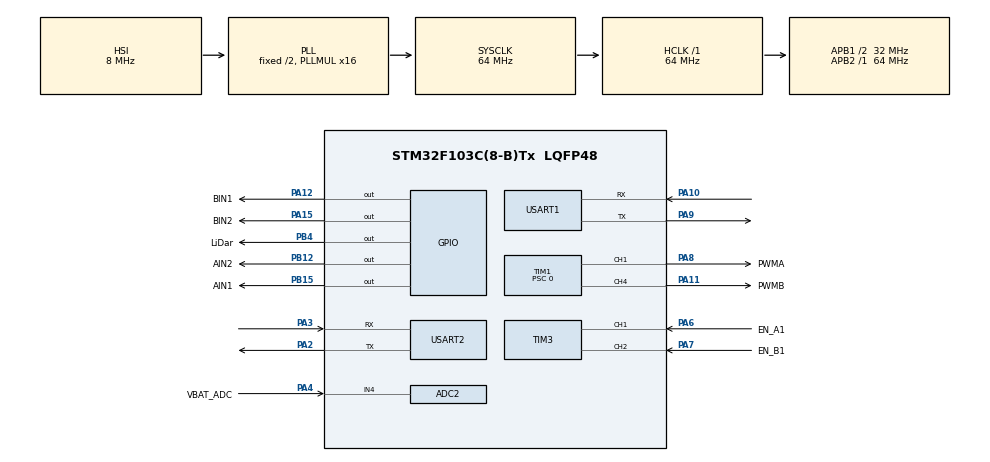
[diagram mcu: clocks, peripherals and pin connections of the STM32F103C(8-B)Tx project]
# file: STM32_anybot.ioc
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ADC2.Channel-0\#ChannelRegularConversion=ADC_CHANNEL_4
ADC2.NbrOfConversionFlag=1
ADC2.Rank-0\#ChannelRegularConversion=1
ADC2.SamplingTime-0\#ChannelRegularConversion=ADC_SAMPLETIME_1CYCLE_5
Mcu.Family=STM32F1
Mcu.Name=STM32F103C(8-B)Tx
Mcu.Package=LQFP48
NVIC.PriorityGroup=NVIC_PRIORITYGROUP_2
NVIC.TIM3_IRQn=true\:1\:0\:true\:false\:true\:true\:true\:true
PA0-WKUP.GPIO_Label=EN_A2
PA0-WKUP.Signal=S_TIM2_CH1_ETR
PA1.GPIO_Label=EN_B2
PA1.Signal=S_TIM2_CH2
PA10.Mode=Asynchronous
PA10.Signal=USART1_RX
PA11.GPIO_Label=PWMB
PA11.Signal=S_TIM1_CH4
PA12.GPIO_Label=BIN1
PA12.GPIO_Speed=GPIO_SPEED_FREQ_HIGH
PA12.Signal=GPIO_Output
PA13.Mode=Serial_Wire
PA13.Signal=SYS_JTMS-SWDIO
PA14.Mode=Serial_Wire
PA14.Signal=SYS_JTCK-SWCLK
PA15.GPIO_Label=BIN2
PA15.GPIO_Speed=GPIO_SPEED_FREQ_HIGH
PA15.Signal=GPIO_Output
PA2.Mode=Asynchronous
PA2.Signal=USART2_TX
PA3.Mode=Asynchronous
PA3.Signal=USART2_RX
PA4.GPIO_Label=VBAT_ADC
PA4.Signal=ADCx_IN4
PA6.GPIO_Label=EN_A1
PA6.Signal=S_TIM3_CH1
PA7.GPIO_Label=EN_B1
PA7.Signal=S_TIM3_CH2
PA8.GPIO_Label=PWMA
PA8.Signal=S_TIM1_CH1
PA9.Mode=Asynchronous
PA9.Signal=USART1_TX
PB12.GPIO_Label=AIN2
PB12.GPIO_Speed=GPIO_SPEED_FREQ_HIGH
PB12.Signal=GPIO_Output
PB15.GPIO_Label=AIN1
PB15.GPIO_Speed=GPIO_SPEED_FREQ_HIGH
PB15.Signal=GPIO_Output
PB4.GPIO_Label=LiDar
PB4.Signal=GPIO_Output
ProjectManager.HeapSize=0x200
ProjectManager.StackSize=0x400
ProjectManager.TargetToolchain=STM32CubeIDE
RCC.ADCPresc=RCC_ADCPCLK2_DIV8
RCC.AHBFreq_Value=64000000
RCC.APB1CLKDivider=RCC_HCLK_DIV2
RCC.APB1Freq_Value=32000000
RCC.APB1TimFreq_Value=64000000
RCC.APB2Freq_Value=64000000
RCC.APB2TimFreq_Value=64000000
RCC.HCLKFreq_Value=64000000
RCC.PLLMUL=RCC_PLL_MUL16
RCC.SYSCLKFreq_VALUE=64000000
RCC.SYSCLKSource=RCC_SYSCLKSOURCE_PLLCLK
RCC.USBFreq_Value=64000000
SH.ADCx_IN4.0=ADC2_IN4,IN4
SH.S_TIM1_CH1.0=TIM1_CH1,PWM Generation1 CH1
SH.S_TIM1_CH4.0=TIM1_CH4,PWM Generation4 CH4
SH.S_TIM2_CH1_ETR.0=TIM2_CH1
SH.S_TIM2_CH2.0=TIM2_CH2
SH.S_TIM3_CH1.0=TIM3_CH1,Encoder_Interface
SH.S_TIM3_CH2.0=TIM3_CH2,Encoder_Interface
TIM1.Channel-PWM\ Generation1\ CH1=TIM_CHANNEL_1
TIM1.Channel-PWM\ Generation4\ CH4=TIM_CHANNEL_4
TIM1.Period=6399
TIM1.Prescaler=0
TIM3.AutoReloadPreload=TIM_AUTORELOAD_PRELOAD_ENABLE
TIM3.EncoderMode=TIM_ENCODERMODE_TI12
USART1.VirtualMode=VM_ASYNC
USART2.VirtualMode=VM_ASYNC
board=custom

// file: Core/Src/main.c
/* USER CODE BEGIN Header */
/**
  ******************************************************************************
  * @file           : main.c
  * @brief          : Main program body
  ******************************************************************************
  * @attention
  *
  * Copyright (c) 2025 STMicroelectronics.
  * All rights reserved.
  *
  * This software is licensed under terms that can be found in the LICENSE file
  * in the root directory of this software component.
  * If no LICENSE file comes with this software, it is provided AS-IS.
  *
  ******************************************************************************
  */
/* USER CODE END Header */
#include "main.h"
#include "adc.h"
#include "tim.h"
#include "usart.h"
#include "gpio.h"

/* USER CODE BEGIN Includes */
#include "retarget.h"
#include "user_main.h"
/* USER CODE END Includes */

void SystemClock_Config(void);

int main(void)
{

  /* MCU Configuration--------------------------------------------------------*/

  /* Reset of all peripherals, Initializes the Flash interface and the Systick. */
  HAL_Init();

  /* Configure the system clock */
  SystemClock_Config();

  /* Initialize all configured peripherals */
  MX_GPIO_Init();
  MX_USART1_UART_Init();
  MX_ADC2_Init();
  MX_USART2_UART_Init();
  MX_TIM1_Init();
  MX_TIM3_Init();
  /* USER CODE BEGIN 2 */
    RetargetInit(&huart1);
  /* USER CODE END 2 */

  /* Infinite loop */
  while (1)
  {

    /* USER CODE BEGIN 3 */
    userMain();
  }
  /* USER CODE END 3 */
}

void SystemClock_Config(void)
{
  RCC_OscInitTypeDef RCC_OscInitStruct = {0};
  RCC_ClkInitTypeDef RCC_ClkInitStruct = {0};
  RCC_PeriphCLKInitTypeDef PeriphClkInit = {0};

  /** Initializes the RCC Oscillators according to the specified parameters
  * in the RCC_OscInitTypeDef structure.
  */
  RCC_OscInitStruct.OscillatorType = RCC_OSCILLATORTYPE_HSI;
  RCC_OscInitStruct.HSIState = RCC_HSI_ON;
  RCC_OscInitStruct.HSICalibrationValue = RCC_HSICALIBRATION_DEFAULT;
  RCC_OscInitStruct.PLL.PLLState = RCC_PLL_ON;
  RCC_OscInitStruct.PLL.PLLSource = RCC_PLLSOURCE_HSI_DIV2;
  RCC_OscInitStruct.PLL.PLLMUL = RCC_PLL_MUL16;
  if (HAL_RCC_OscConfig(&RCC_OscInitStruct) != HAL_OK)
  {
    Error_Handler();
  }

  /** Initializes the CPU, AHB and APB buses clocks
  */
  RCC_ClkInitStruct.ClockType = RCC_CLOCKTYPE_HCLK|RCC_CLOCKTYPE_SYSCLK
                              |RCC_CLOCKTYPE_PCLK1|RCC_CLOCKTYPE_PCLK2;
  RCC_ClkInitStruct.SYSCLKSource = RCC_SYSCLKSOURCE_PLLCLK;
  RCC_ClkInitStruct.AHBCLKDivider = RCC_SYSCLK_DIV1;
  RCC_ClkInitStruct.APB1CLKDivider = RCC_HCLK_DIV2;
  RCC_ClkInitStruct.APB2CLKDivider = RCC_HCLK_DIV1;

  if (HAL_RCC_ClockConfig(&RCC_ClkInitStruct, FLASH_LATENCY_2) != HAL_OK)
  {
    Error_Handler();
  }
  PeriphClkInit.PeriphClockSelection = RCC_PERIPHCLK_ADC;
  PeriphClkInit.AdcClockSelection = RCC_ADCPCLK2_DIV8;
  if (HAL_RCCEx_PeriphCLKConfig(&PeriphClkInit) != HAL_OK)
  {
    Error_Handler();
  }
}

void Error_Handler(void)
{
  __disable_irq();
  while (1)
  {
  }
}
